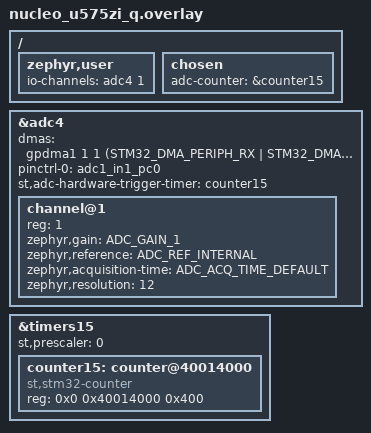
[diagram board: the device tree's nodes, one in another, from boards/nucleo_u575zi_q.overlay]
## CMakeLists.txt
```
cmake_minimum_required(VERSION 3.20.0)

find_package(Zephyr REQUIRED HINTS $ENV{ZEPHYR_BASE})
project(hardware_trigger)

target_sources(app PRIVATE src/main.c)
```

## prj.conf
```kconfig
# ADC
CONFIG_ADC=y
CONFIG_ADC_ASYNC=y
CONFIG_ADC_STM32=y
CONFIG_ADC_STM32_DMA=y
CONFIG_ADC_STM32_DMA_HARDWARE_TRIGGER=y

# Counter
CONFIG_COUNTER=y
CONFIG_COUNTER_TIMER_STM32=y

# Polling
CONFIG_POLL=y

CONFIG_LOG=y
```

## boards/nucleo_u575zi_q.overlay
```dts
/ {
    zephyr,user {
        io-channels = <&adc4 1>;
    };

    chosen {
        adc-counter = &counter15;
    };
};

&adc4 {
    #address-cells = <1>;
    #size-cells = <0>;

    dmas = <&gpdma1 1 1 (STM32_DMA_PERIPH_RX | STM32_DMA_MEM_16BITS | STM32_DMA_PERIPH_16BITS)>;
    dma-names = "gpdma";
    pinctrl-0 = <&adc1_in1_pc0>;
    st,adc-hardware-trigger-timer = <&counter15>;

    channel@1 {
        reg = <1>;
        zephyr,gain = "ADC_GAIN_1";
        zephyr,reference = "ADC_REF_INTERNAL";
        zephyr,acquisition-time = <ADC_ACQ_TIME_DEFAULT>;
        zephyr,resolution = <12>;
    };
};

&timers15 {
    status = "okay";
    st,prescaler = <0>;

    counter15: counter@40014000 {
        compatible = "st,stm32-counter";
        reg = <0x0 0x40014000 0x400>;
        status = "okay";
    };
};
```

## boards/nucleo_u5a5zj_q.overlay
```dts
/ {
    zephyr,user {
        io-channels = <&adc4 1>;
    };

    chosen {
        adc-counter = &counter15;
    };
};

&adc4 {
    #address-cells = <1>;
    #size-cells = <0>;

    dmas = <&gpdma1 1 1 (STM32_DMA_PERIPH_RX | STM32_DMA_MEM_16BITS | STM32_DMA_PERIPH_16BITS)>;
    dma-names = "gpdma";
    pinctrl-0 = <&adc1_in1_pc0>;
    st,dma-trigger-timer = <&counter15>;

    channel@1 {
        reg = <1>;
        zephyr,gain = "ADC_GAIN_1";
        zephyr,reference = "ADC_REF_INTERNAL";
        zephyr,acquisition-time = <ADC_ACQ_TIME_DEFAULT>;
        zephyr,resolution = <12>;
    };
};

&timers15 {
    status = "okay";
    st,prescaler = <0>;

    counter15: counter@40014000 {
        compatible = "st,stm32-counter";
        reg = <0x0 0x40014000 0x400>;
        status = "okay";
    };
};
```

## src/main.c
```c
#include <zephyr/drivers/adc.h>
#include <zephyr/drivers/counter.h>
#include <zephyr/logging/log.h>

LOG_MODULE_REGISTER(main, 4);

#define SAMPLING_RATE 8000

enum adc_action sample_end_event(const struct device* dev, const struct adc_sequence* sequence, uint16_t sampling_index);

const struct device* timer = DEVICE_DT_GET(DT_CHOSEN(adc_counter));
struct counter_top_cfg timer_cfg;

struct adc_dt_spec channel = ADC_DT_SPEC_GET(DT_PATH(zephyr_user));
struct adc_sequence_options opts = {
    .callback = sample_end_event,
};

struct k_poll_signal signal;
uint16_t sample[16000] = { 0 };
struct adc_sequence seq = {
    .buffer = sample,
    .buffer_size = sizeof(sample),
};


int main(void){
    seq.options = &opts;
    timer_cfg.ticks = (counter_get_frequency(timer) / SAMPLING_RATE);
    timer_cfg.flags = 0;
 

    (void)k_poll_signal_init(&signal);

    int err = adc_sequence_init_dt(&channel, &seq);
    if (err){
        LOG_ERR("Failed to init sequence");
        return err;
    }

    err = counter_set_top_value(timer, &timer_cfg);
    if (err){
        LOG_ERR("Failed to set timer configuration");
        return err;
    }

    err = adc_read_async_dt(&channel, &seq, &signal);
    if (err){
        LOG_ERR("Failed to start reading");
        return err;
    }

    return 0;
}

enum adc_action sample_end_event(const struct device* dev, const struct adc_sequence* sequence, uint16_t sampling_index){
    LOG_DBG("Finished sampling for 2 seconds");
    LOG_HEXDUMP_INF(sample, 20, "Buffer values are: ");
    
    return ADC_ACTION_FINISH;
}
```
